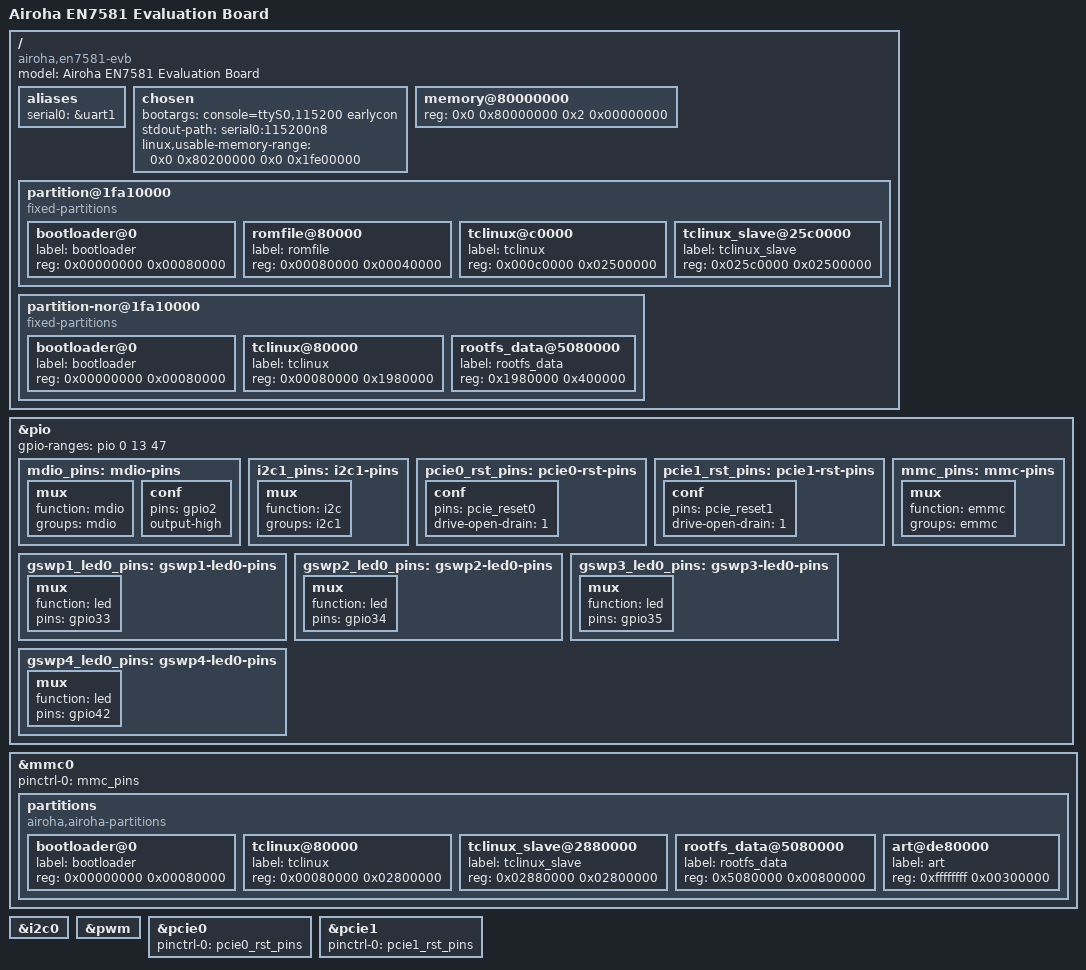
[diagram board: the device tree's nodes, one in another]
// SPDX-License-Identifier: (GPL-2.0-only OR BSD-2-Clause)
/dts-v1/;

/* Bootloader installs ATF here */
/memreserve/ 0x80000000 0x200000;

#include <dt-bindings/leds/common.h>
#include <dt-bindings/gpio/gpio.h>
#include "en7581.dtsi"

/ {
	model = "Airoha EN7581 Evaluation Board";
	compatible = "airoha,en7581-evb", "airoha,en7581";

	aliases {
		serial0 = &uart1;
	};

	chosen {
		bootargs = "console=ttyS0,115200 earlycon";
		stdout-path = "serial0:115200n8";
		linux,usable-memory-range = <0x0 0x80200000 0x0 0x1fe00000>;
	};

	memory@80000000 {
		device_type = "memory";
		reg = <0x0 0x80000000 0x2 0x00000000>;
	};

	partition@1fa10000 {
		compatible = "fixed-partitions";
		#address-cells = <1>;
		#size-cells = <1>;

		bootloader@0 {
			label = "bootloader";
			reg = <0x00000000 0x00080000>;
		};
		romfile@80000 {
			label = "romfile";
			reg = <0x00080000 0x00040000>;
		};
		tclinux@c0000 {
			label = "tclinux";
			reg = <0x000c0000 0x02500000>;
		};
		tclinux_slave@25c0000 {
			label = "tclinux_slave";
			reg = <0x025c0000 0x02500000>;
		};
	};

	partition-nor@1fa10000 {
		compatible = "fixed-partitions";
		#address-cells = <1>;
		#size-cells = <1>;

		bootloader@0 {
			label = "bootloader";
			reg = <0x00000000 0x00080000>;
		};
		tclinux@80000 {
			label = "tclinux";
			reg = <0x00080000 0x1980000>;
		};
		rootfs_data@5080000 {
			label = "rootfs_data";
			reg = <0x1980000 0x400000>;
		};
	};
};

&pio {
	gpio-ranges = <&pio 0 13 47>;

	mdio_pins: mdio-pins {
		mux {
			function = "mdio";
			groups = "mdio";
		};

		conf {
			pins = "gpio2";
			output-high;
		};
	};

	i2c1_pins: i2c1-pins {
		mux {
			function = "i2c";
			groups = "i2c1";
		};
	};

	pcie0_rst_pins: pcie0-rst-pins {
		conf {
			pins = "pcie_reset0";
			drive-open-drain = <1>;
		};
	};

	pcie1_rst_pins: pcie1-rst-pins {
		conf {
			pins = "pcie_reset1";
			drive-open-drain = <1>;
		};
	};

	gswp1_led0_pins: gswp1-led0-pins {
		mux {
			function = "led";
			pins = "gpio33";
		};
	};

	gswp2_led0_pins: gswp2-led0-pins {
		mux {
			function = "led";
			pins = "gpio34";
		};
	};

	gswp3_led0_pins: gswp3-led0-pins {
		mux {
			function = "led";
			pins = "gpio35";
		};
	};

	gswp4_led0_pins: gswp4-led0-pins {
		mux {
			function = "led";
			pins = "gpio42";
		};
	};

	mmc_pins: mmc-pins {
		mux {
			function = "emmc";
			groups = "emmc";
		};
	};
};

&mmc0 {
	pinctrl-names = "default";
	pinctrl-0 = <&mmc_pins>;
	status = "okay";

	partitions {
		compatible = "airoha,airoha-partitions";
		#address-cells = <1>;
		#size-cells = <1>;

		bootloader@0 {
			label = "bootloader";
			reg = <0x00000000 0x00080000>;
		};
		tclinux@80000 {
			label = "tclinux";
			reg = <0x00080000 0x02800000>;
		};
		tclinux_slave@2880000 {
			label = "tclinux_slave";
			reg = <0x02880000 0x02800000>;
		};
		rootfs_data@5080000 {
			label = "rootfs_data";
			reg = <0x5080000 0x00800000>;
		};
		art@de80000 {
			label = "art";
			reg = <0xffffffff 0x00300000>;
		};
	};
};

&i2c0 {
	status = "okay";
};

&pwm {
	status = "okay";
};

&pcie0 {
	pinctrl-names = "default";
	pinctrl-0 = <&pcie0_rst_pins>;
	status = "okay";
};

&pcie1 {
	pinctrl-names = "default";
	pinctrl-0 = <&pcie1_rst_pins>;
	status = "okay";
};
